# CYBLE_416045_02 register map
File version: 0.1
PSoC 63
Registers are 32-bit, read-write, no defined reset value unless marked. A register's access mark holds for its fields unless they carry their own. Offsets are from the block's base; lines under a group give offsets from that group; [hi:lo] are bit positions; {n}, {i} and the like mark numbered series; 'fields as' and 'values as' point back to an identical list; <NAME> marks a mode.

## Memory map
0x00000000 CapSense_1

## CapSense_1
Base 0x00000000
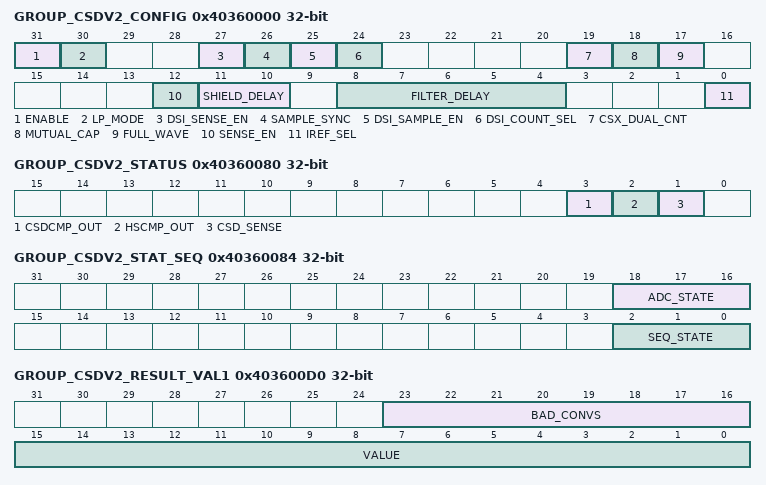
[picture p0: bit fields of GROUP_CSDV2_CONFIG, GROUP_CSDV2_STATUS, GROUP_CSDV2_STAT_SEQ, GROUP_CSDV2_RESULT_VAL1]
0x40360000 GROUP_CSDV2_CONFIG — Configuration and Control
  [31] ENABLE — Master enable of the CSDv2 IP. Must be set to 1 for any CSDv2, ADC or IDAC operation to function.?When 0 all analog components will be off and all switches will be open.
  [30] LP_MODE — Select the power mode for the CSD components (REFGEN, AMBUF, CSDCMP, HSCMP):?0: High Power mode?1: Low Power mode
  [27] DSI_SENSE_EN — Enables the use of the dsi_sense_in input instead of the internally generated modulation signal to drive csd_sense and csd_shield signals.
  [26] SAMPLE_SYNC — Enables double synchronizing of sample input from DSI (only relevant when DSI_SAMPLE_EN=1).
  [25] DSI_SAMPLE_EN — Enables the use of the dsi_sample_in input instead of the comparator output to strobe COUNTER.
  [24] DSI_COUNT_SEL — Select what to output on the dsi_count bus.
    0=CSD_RESULT (depending on the dsi_count_val_sel input either output RESULT_VAL1.VALUE (0) or RESULT_VAL2.VALUE (1) on the dsi_count bus. Note that dsi_count_val_sel is not synchronized, i.e. it controls the mux combinatorially.); 1=ADC_RESULT (output ADC_RES.VIN_CNT on the dsi_count bus)
  [19] CSX_DUAL_CNT — Enable the use of two counters for MUTUAL cap sensing mode (CSX), do not use when MUTUAL_CAP=0
    0=ONE (Use one counter for both phases (source and sink).); 1=TWO (Use two counters, separate count for when csd_sense is high and when csd_sense is low.)
  [18] MUTUAL_CAP — Enables mutual cap sensing mode
    0=SELFCAP (Self-cap mode (configure sense line as CSD_SENSE)); 1=MUTUALCAP (Mutual-cap mode (configure Tx line as CSD_SENSE, inverted Tx line as CSD_SHIELD and Rx Line as AMUXA). In this mode the polarity bit of the IDAC is controlled by csd_sense.)
  [17] FULL_WAVE — Enables full wave cap sensing mode
    0=HALFWAVE (Half Wave mode (normal).?In this mode the comparator always trips in the same direction (positive or negative edge) and the same Vref, i.e. no polarity change.); 1=FULLWAVE (Full Wave mode.?In this mode the comparator trips in opposite direction and with different Vref in each phase, i.e. the polarity flips.)
  [12] SENSE_EN — Enables the sense modulator output. ?0: all switches, static or dynamic, are open and IDAC in CSD mode is off?1: switches and IDAC can be closed/on as per MMIO setting and CSD sequencer.
  [11:10] SHIELD_DELAY — Selects the delay by which csd_shield is delayed relative to csd_sense.
    0=OFF (Delay line is off, csd_shield=csd_sense); 1=D5NS (Introduces a 5ns delay (typ)); 2=D10NS (Introduces a 10ns delay (typ)); 3=D20NS (Introduces a 20ns delay (typ))
  [8:4] FILTER_DELAY — This value determines the number of cycles that the digital filter makes the CSDCMP output ignored while the counter counts and IDAC is on. ?When set to 0 the digital filter is off. When set to any other value the ignoring will last for FILTER_DELAY clk_csd cycles after the start of each measurement and from the first comparator trip to the end of each measurement.
  [0] IREF_SEL — Select Iref supply.
    0=IREF_SRSS (select SRSS Iref (default)); 1=IREF_PASS (select PASS.AREF Iref, only available if PASS IP is on the chip.)
0x40360004 GROUP_CSDV2_SPARE — Spare MMIO
  [3:0] SPARE
0x40360080 GROUP_CSDV2_STATUS — Status Register
  [3] CSDCMP_OUT ro — Output of main sensing comparator (synchronized)
  [2] HSCMP_OUT ro — Output of reference buffer comparator used to charge up Cmod and/or Csh_tank (synchronized)
    0=C_LT_VREF (Vin < Vref); 1=C_GT_VREF (Vin > Vref)
  [1] CSD_SENSE ro — Signal used to drive the Cs switches.
0x40360084 GROUP_CSDV2_STAT_SEQ — Current Sequencer status
  [18:16] ADC_STATE ro — ADC sequencer state (only relevant after SEQ_STATE has reached SAMPLE_NORM and ADC sequencer has started)
  [2:0] SEQ_STATE ro — CSD sequencer state
0x40360088 GROUP_CSDV2_STAT_CNTS — Current status counts
  [15:0] NUM_CONV ro — Current number of conversions remaining when in Sample_* states (note that in AutoZero* states the same down counter is reused to count the cycles)
0x403600D0 GROUP_CSDV2_RESULT_VAL1 — Result CSD/CSX accumulation counter value 1
  [23:16] BAD_CONVS ro — Number of 'bad' conversion for which the CSD comparator did not trigger within the normal time window, either because Vref was not crossed at all, or if the Vref was already crossed before the window started. This counter is reset when the sequencer is started and will saturate at 255 when more than 255 conversions are bad.
  [15:0] VALUE ro — Accumulated counter value for this result. In case of Mutual cap with two counters (CSX = config.mutual_cap & config.csx_dual_cnt) this counter counts when csd_sense is high.
0x403600D4 GROUP_CSDV2_RESULT_VAL2 — Result CSX accumulation counter value 2
  [15:0] VALUE ro — Only used in case of Mutual cap with two counters (CSX = config.mutual_cap & config.csx_dual_cnt), this counter counts when csd_sense is low.
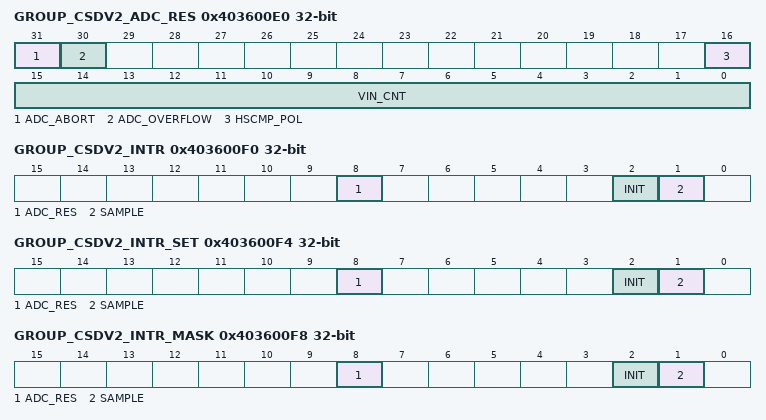
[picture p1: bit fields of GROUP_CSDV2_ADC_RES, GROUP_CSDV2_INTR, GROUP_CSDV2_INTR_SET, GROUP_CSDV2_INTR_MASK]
0x403600E0 GROUP_CSDV2_ADC_RES — ADC measurement
  [31] ADC_ABORT ro — This flag is set when the ADC sequencer was aborted before tripping HSCMP.
  [30] ADC_OVERFLOW ro — This flag is set when the ADC counter overflows. This is an indication to the firmware that the IDACB current level is too low.
  [16] HSCMP_POL ro — Polarity used for IDACB for this last ADC result, 0= source, 1= sink
  [15:0] VIN_CNT ro — Count to source/sink Cref1 + Cref2 from Vin to Vrefhi. This is also the current counter value for the HSCMP counter
0x403600F0 GROUP_CSDV2_INTR — CSD Interrupt Request Register
  [8] ADC_RES — ADC Result ready
  [2] INIT — Coarse initialization complete or Sample initialization complete (the latter is typically ignored)
  [1] SAMPLE — A normal sample is complete
0x403600F4 GROUP_CSDV2_INTR_SET — CSD Interrupt set register
  [8] ADC_RES — Write with '1' to set corresponding bit in interrupt request register.
  [2] INIT — Write with '1' to set corresponding bit in interrupt request register.
  [1] SAMPLE — Write with '1' to set corresponding bit in interrupt request register.
0x403600F8 GROUP_CSDV2_INTR_MASK — CSD Interrupt mask register
  [8] ADC_RES — Mask bit for corresponding bit in interrupt request register.
  [2] INIT — Mask bit for corresponding bit in interrupt request register.
  [1] SAMPLE — Mask bit for corresponding bit in interrupt request register.
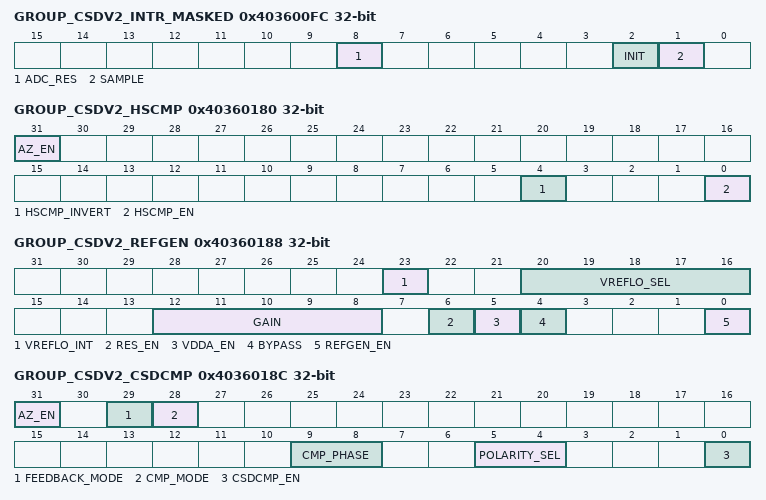
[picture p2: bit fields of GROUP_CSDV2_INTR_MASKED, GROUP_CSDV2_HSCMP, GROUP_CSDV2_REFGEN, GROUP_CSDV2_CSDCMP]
0x403600FC GROUP_CSDV2_INTR_MASKED — CSD Interrupt masked register
  [8] ADC_RES ro — Logical and of corresponding request and mask bits.
  [2] INIT ro — Logical and of corresponding request and mask bits.
  [1] SAMPLE ro — Logical and of corresponding request and mask bits.
0x40360180 GROUP_CSDV2_HSCMP — High Speed Comparator configuration
  [31] AZ_EN — Auto-Zero enable, allow the Sequencer to Auto-Zero this component
  [4] HSCMP_INVERT — Invert the HSCMP output before it is used to control switches and the CSD sequencer. This bit does not affect the ADC sequencer or the STATUS.HSCMP_OUT
  [0] HSCMP_EN — High Speed Comparator enable
    0=OFF (Disable comparator, output is zero); 1=ON (On, regular operation. Note that CONFIG.LP_MODE determines the power mode level)
0x40360184 GROUP_CSDV2_AMBUF — Reference Generator configuration
  [1:0] PWR_MODE — Amux buffer power level
    0=OFF (Disable buffer); 1=NORM (On, normal or low power level depending on CONFIG.LP_MODE.); 2=HI (On, high or low power level depending on CONFIG.LP_MODE.)
0x40360188 GROUP_CSDV2_REFGEN — Reference Generator configuration
  [23] VREFLO_INT — Ouput the resistor string tap either to Vreflo (0) or Vreflo_int (1).
  [20:16] VREFLO_SEL — Select resistor string tap for Vreflo/Vreflo_int, 0= minimum vout, 31= maximum vout = vrefhi (only works if the resistor string is enabled; RES_EN=1)
  [12:8] GAIN — Select resistor string tap for feedback, 0= minimum vout, 31= maximum vout = vrefhi -> gain=1 (only works if the resistor string is enabled; RES_EN=1)
  [6] RES_EN — Resistor string enable; 0= open switch on top of the resistor string (Vreflo=Vssa)
  [5] VDDA_EN — Close Vdda switch to top of resistor string (or Vrefhi?)
  [4] BYPASS — Bypass selected input reference unbuffered to Vrefhi
  [0] REFGEN_EN — Reference Generator Enable
    0=OFF (Disable Reference Generator); 1=ON (On, regular operation. Note that CONFIG.LP_MODE determines the power mode level)
0x4036018C GROUP_CSDV2_CSDCMP — CSD Comparator configuration
  [31] AZ_EN — Auto-Zero enable, allow the Sequencer to Auto-Zero this component
  [29] FEEDBACK_MODE — This bit controls whether the output directly from the comparator (csdcmp_out) or the flopped version (csdcmp_out_ff) is used. For CSD operation, the selected signal controls the IDAC(s), in GP mode the signal goes out on dsi_sample_out.
    0=FLOP (Use feedback from sampling flip-flop (used in most modes).); 1=COMP (Use feedback from comparator directly (used in single Cmod mutual cap sensing only))
  [28] CMP_MODE — Select which signal to output on dsi_sample_out.
    0=CSD (CSD mode: output the filtered sample signal on dsi_sample_out); 1=GP (General Purpose mode: output the unfiltered sample unfiltered comparator output, either asynchronous or flopped.)
  [9:8] CMP_PHASE — Select in what phase(s) the comparator is active, typically set to match the BAL_MODE of the used IDAC. Note, this also determines when a bad conversion is detected, namely at the beginning and end of the comparator active phase (also taking into account FILTER_DELAY and non-overlap).
    0=FULL (Comparator is active from start of Phi2 and kept active into Phi1. Intended usage: legacy CSD for balancing over a full csd_sense period (non-overlap should be turned off)); 1=PHI1 (Comparator is active during Phi1 only. Currently no known use-case.); 2=PHI2 (Comparator is active during Phi2 only. Intended usage: CSD Low EMI.); 3=PHI1_2 (Comparator is activated at the start of both Phi1 and Phi2 (non-overlap should be enabled). Intended usage: CSX, or Full-Wave.)
  [5:4] POLARITY_SEL — Select which IDAC polarity to use to detect CSDCMP triggering
    0=IDACA_POL (Use idaca_pol (firmware setting with CSX and optionally DSI mixed in) to determine the direction, this is the most common use-case, used for normal CSD and normal CSX); 1=IDACB_POL (Use idacb_pol (firmware setting with optional DSI mixed in) to determine the direction, this is only used for normal CSD if IDACB is used i.s.o. IDACA (not common)); 2=DUAL_POL (Use the expression (csd_sense ? idaca_pol : idacb_pol) to determine the direction, this is only useful for the CSX with DUAL_IDAC use-case)
  [0] CSDCMP_EN — CSD Comparator Enable
    values as GROUP_CSDV2_HSCMP.HSCMP_EN
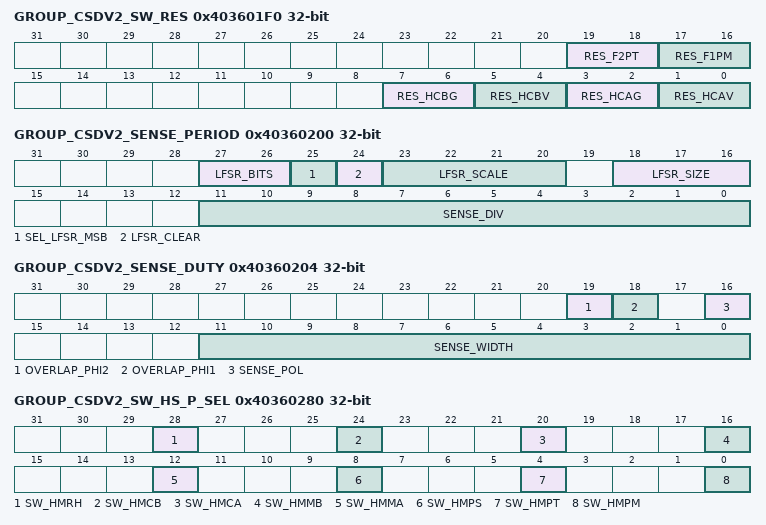
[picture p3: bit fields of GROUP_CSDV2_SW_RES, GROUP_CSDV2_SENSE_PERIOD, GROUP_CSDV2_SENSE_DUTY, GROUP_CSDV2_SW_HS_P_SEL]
0x403601F0 GROUP_CSDV2_SW_RES — Switch Resistance configuration
  [19:18] RES_F2PT — Select resistance for the corresponding switch
  [17:16] RES_F1PM — Select resistance for the corresponding switch
    0=LOW; 1=MED (Medium); 2=HIGH
  [7:6] RES_HCBG — Select resistance or low EMI for the corresponding switch
  [5:4] RES_HCBV — Select resistance or low EMI for the corresponding switch
  [3:2] RES_HCAG — Select resistance or low EMI for the corresponding switch
  [1:0] RES_HCAV — Select resistance or low EMI (slow ramp) for the HCAV switch
    0=LOW; 1=MED (Medium); 2=HIGH; 3=LOWEMI (Low EMI (slow ramp: 3 switches closed by fixed delay line))
0x40360200 GROUP_CSDV2_SENSE_PERIOD — Sense clock period
  [27:26] LFSR_BITS — Selects the number of LSB bits to use from the LSFR to provide the clock dithering variation on the base period.?Caveat make sure that SENSE_DIV > the maximum absolute range (e.g. for 4B SENSE_DIV > 8), otherwise results are undefined.
    0=Cy2B (use 2 bits: range = [-2,1]); 1=Cy3B (use 3 bits: range = [-4,3]); 2=Cy4B (use 4 bits: range = [-8,7]); 3=Cy5B (use 5 bits: range = [-16,15] (default))
  [25] SEL_LFSR_MSB — Use the MSB of configured LSFR size as csd_sense signal. Intended to be used only with bit 8 or 12-bit LFSR size for CSDv1 backward compatibility (PRS). When this bit is set then clock divider dithering is disabled and SENSE_WIDTH is disabled.
  [24] LFSR_CLEAR — When set, forces the LFSR to it's initial state (all ones). This bit is automatically cleared by hardware after the LFSR is cleared, which is at the next clk_csd positive edge. This bit should be set whenever this register is written and the LFSR is used.?Note that the LFSR will also get reset to all ones during the AutoZero_1/2 states.
  [23:20] LFSR_SCALE — Shift the LFSR output left by LSFR_SCALE bits before adding to SENSE_DIV. This dithering is disabled when SEL_LSFR_MSB is set.?The clock divider to be used = (SENSE_DIV+1) + (SEL_LSFR_MSB ? 0 : (LFSR_OUT<<LFSR_SCALE)).?Note that the clock divider including the dithering term must fit in 12 bits, otherwise the result is undefined.
  [18:16] LFSR_SIZE — Selects the length of the LFSR which determines the LFSR repeat period. LFSR_BITS LSB of the LFSR are used for the clock dithering variation on the base period (was PRS in CSDv1). Whenever the LFSR is used (non zero value in this field) the LFSR_CLEAR bit should also be set.
    0=OFF (Don't use clock dithering (=spreadspectrum) (LFSR output value is zero)); 1=Cy6B (6-bit LFSR (G(x)=X^6 +X^4+X^3+ X+1, period= 63)); 2=Cy7B (7-bit LFSR (G(x)=X^7 +X^4+X^3+X^2+1, period= 127)); 3=Cy9B (9-bit LFSR (G(x)=X^9 +X^4+X^3+ X+1, period= 511)); 4=Cy10B (10-bit LFSR (G(x)=X^10+X^4+X^3+ X+1, period= 1023)); 5=Cy8B (8-bit LFSR (G(x)=X^8+X^4+X^3+X^2+1, period= 255)); 6=Cy12B (12-bit LFSR (G(x)=X^12+X^7+X^4+X^3+1, period= 4095))
  [11:0] SENSE_DIV — The length-1 of the Sense modulation 'clock' period in clk_csd cycles. For regular CSD one sense clock cycle = one conversion (=phi1+phi2) .?Note this is the base divider, clock dithering may change the actual period length.?Note that SENSE_DIV must be at least 1 and additionally also allow for one clk_hf of non overlap (if OVERLAP_HI1/2 is set) on both phases, i.e. if clk_csd=clk_hf then SENSE_DIV must be >=3.?In addition the FILTER_DELAY needs to be added to the minimum allowed SENSE_DIV value.
0x40360204 GROUP_CSDV2_SENSE_DUTY — Sense clock duty cycle
  [19] OVERLAP_PHI2 — Same as OVERLAP_PHI1 but for Phi2 (csd_sense=1).
  [18] OVERLAP_PHI1 — NonOverlap or not for Phi1 (csd_sense=0).?0 = Non-overlap for Phi1, the Phi1 signal is csd_sense inverted except that the signal goes low 1 clk_sample before csd_sense goes high. Intended usage: new low EMI CSD/CSX with static GPIO.?1 = 'Overlap' (= not non-overlap) for Phi1, the Phi1 signal is csd_sense inverted. Intended usage: legacy CSD with GPIO switching, the GPIO internal circuit ensures that the switches are non-overlapping.
  [16] SENSE_POL — Polarity of the sense clock?0 = start with low phase (typical for regular negative transfer CSD)?1 = start with high phase
  [11:0] SENSE_WIDTH — Defines the length of the first phase of the sense clock in clk_csd cycles. ?A value of 0 disables this feature and the duty cycle of csd_sense will be 50%, which is equal to SENSE_WIDTH = (SENSE_DIV+1)/2, or when clock dithering is used that becomes [(SENSE_DIV+1) + (LFSR_OUT << LSFR_SCALE)]/2. At all times it must be assured that the phases are at least 2 clk_csd cycles (1 for non overlap, if used), if this rule is violated the result is undefined.?Note that this feature is not available when SEL_LFSR_MSB (PRS) is selected.
0x40360280 GROUP_CSDV2_SW_HS_P_SEL — HSCMP Pos input switch Waveform selection
  [28] SW_HMRH — Set corresponding switch
  [24] SW_HMCB — Set corresponding switch
  [20] SW_HMCA — Set corresponding switch
  [16] SW_HMMB — Set corresponding switch
  [12] SW_HMMA — Set corresponding switch
  [8] SW_HMPS — Set corresponding switch
  [4] SW_HMPT — Set corresponding switch
  [0] SW_HMPM — Set HMPM switch?0: static open?1: static closed
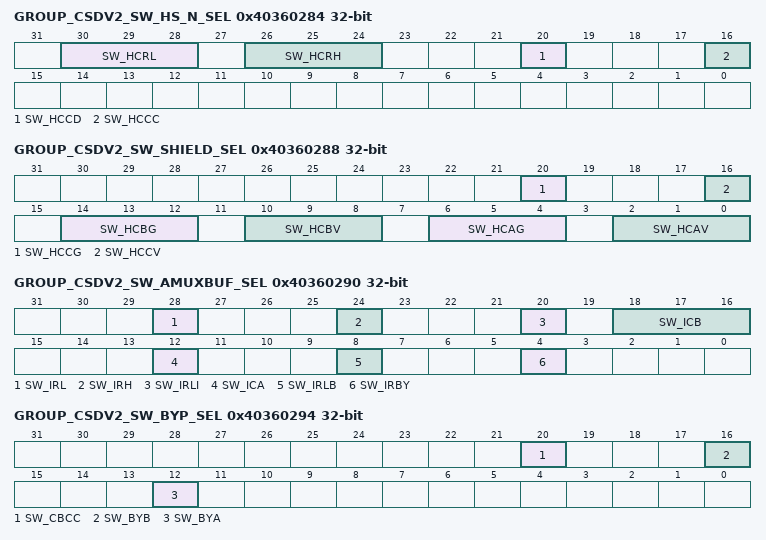
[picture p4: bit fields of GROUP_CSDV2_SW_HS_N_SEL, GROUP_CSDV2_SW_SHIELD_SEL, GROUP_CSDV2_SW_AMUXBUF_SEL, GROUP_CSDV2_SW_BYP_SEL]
0x40360284 GROUP_CSDV2_SW_HS_N_SEL — HSCMP Neg input switch Waveform selection
  [30:28] SW_HCRL — Select waveform for corresponding switch
  [26:24] SW_HCRH — Select waveform for corresponding switch
  [20] SW_HCCD — Set corresponding switch
  [16] SW_HCCC — Set corresponding switch
0x40360288 GROUP_CSDV2_SW_SHIELD_SEL — Shielding switches Waveform selection
  [20] SW_HCCG — Set corresponding switch?If the ADC is enabled then this switch is directly controlled by the ADC sequencer.
  [16] SW_HCCV — Set corresponding switch
  [14:12] SW_HCBG — Select waveform for corresponding switch, using csd_shield as base
  [10:8] SW_HCBV — Select waveform for HCBV switch. The waveform for this switch follows the csd_shield signal, i.e. phi1 and phi2 are delayed with SHIELD_DELAY w.r.t. the csd_sense phases. Only this switch and HCBG use csd_shield as base all other switches use csd_sense as base.?0: static open?1: static closed?2: phi1_delay?3: phi2_delay?4: phi1_delay & HSCMP?5: phi2_delay & HSCMP?6: HSCMP (ignores phi1/2)?7: Reserved
  [6:4] SW_HCAG — Select waveform for corresponding switch
  [2:0] SW_HCAV — Select waveform for HCAV switch using csd_sense as base?0: static open?1: static closed?2: phi1?3: phi2?4: phi1 & HSCMP?5: phi2 & HSCMP?6: HSCMP (ignores phi1/2)?7: Reserved
0x40360290 GROUP_CSDV2_SW_AMUXBUF_SEL — Amuxbuffer switches Waveform selection
  [28] SW_IRL — Set corresponding switch
  [24] SW_IRH — Set corresponding switch
  [20] SW_IRLI — Set corresponding switch
  [18:16] SW_ICB — Select waveform for corresponding switch
  [12] SW_ICA — Set corresponding switch
  [8] SW_IRLB — Set corresponding switch
  [4] SW_IRBY — Set corresponding switch
0x40360294 GROUP_CSDV2_SW_BYP_SEL — AMUXBUS bypass switches Waveform selection
  [20] SW_CBCC — Set corresponding switch?If the ADC is enabled then this switch is directly controlled by the ADC sequencer.
  [16] SW_BYB — Set corresponding switch
  [12] SW_BYA — Set corresponding switch
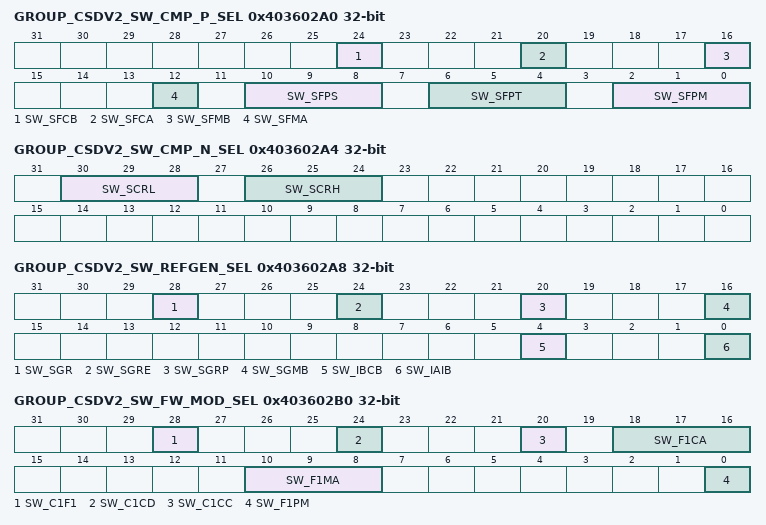
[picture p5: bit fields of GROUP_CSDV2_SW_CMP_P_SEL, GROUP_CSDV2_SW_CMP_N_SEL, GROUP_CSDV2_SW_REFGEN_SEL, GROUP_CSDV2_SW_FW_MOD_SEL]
0x403602A0 GROUP_CSDV2_SW_CMP_P_SEL — CSDCMP Pos Switch Waveform selection
  [24] SW_SFCB — Set corresponding switch
  [20] SW_SFCA — Set corresponding switch
  [16] SW_SFMB — Set corresponding switch
  [12] SW_SFMA — Set corresponding switch
  [10:8] SW_SFPS — Select waveform for corresponding switch
  [6:4] SW_SFPT — Select waveform for corresponding switch
  [2:0] SW_SFPM — Select waveform for corresponding switch
0x403602A4 GROUP_CSDV2_SW_CMP_N_SEL — CSDCMP Neg Switch Waveform selection
  [30:28] SW_SCRL — Select waveform for corresponding switch
  [26:24] SW_SCRH — Select waveform for corresponding switch
0x403602A8 GROUP_CSDV2_SW_REFGEN_SEL — Reference Generator Switch Waveform selection
  [28] SW_SGR — Set corresponding switch
  [24] SW_SGRE — Set corresponding switch
  [20] SW_SGRP — Set corresponding switch
  [16] SW_SGMB — Set corresponding switch
  [4] SW_IBCB — Set corresponding switch
  [0] SW_IAIB — Set corresponding switch
0x403602B0 GROUP_CSDV2_SW_FW_MOD_SEL — Full Wave Cmod Switch Waveform selection
  [28] SW_C1F1 — Set corresponding switch
  [24] SW_C1CD — Set corresponding switch
  [20] SW_C1CC — Set corresponding switch
  [18:16] SW_F1CA — Select waveform for corresponding switch
  [10:8] SW_F1MA — Select waveform for corresponding switch
  [0] SW_F1PM — Set corresponding switch
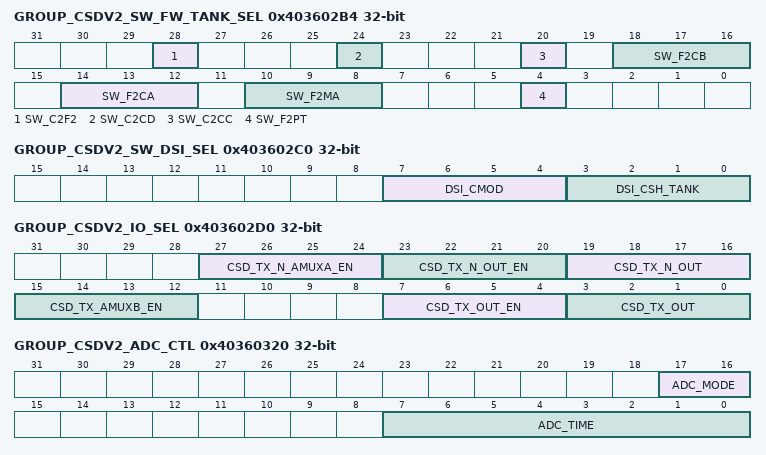
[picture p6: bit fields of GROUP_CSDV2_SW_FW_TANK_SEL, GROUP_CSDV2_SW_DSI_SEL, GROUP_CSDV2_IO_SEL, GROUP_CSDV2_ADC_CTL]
0x403602B4 GROUP_CSDV2_SW_FW_TANK_SEL — Full Wave Csh_tank Switch Waveform selection
  [28] SW_C2F2 — Set corresponding switch
  [24] SW_C2CD — Set corresponding switch
  [20] SW_C2CC — Set corresponding switch
  [18:16] SW_F2CB — Select waveform for corresponding switch
  [14:12] SW_F2CA — Select waveform for corresponding switch
  [10:8] SW_F2MA — Select waveform for corresponding switch
  [4] SW_F2PT — Set corresponding switch
0x403602C0 GROUP_CSDV2_SW_DSI_SEL — DSI output switch control Waveform selection
  [7:4] DSI_CMOD — Select waveform for dsi_cmod output signal
  [3:0] DSI_CSH_TANK — Select waveform for dsi_csh_tank output signal?0: static open?1: static closed?2: phi1?3: phi2?4: phi1 & HSCMP?5: phi2 & HSCMP?6: HSCMP // ignores phi1/2?7: !sense // = phi1 but ignores OVERLAP_PHI1??8: phi1_delay // phi1 delayed with shield delay?9: phi2_delay // phi2 delayed with shield delay??10: !phi1?11: !phi2?12: !(phi1 & HSCMP)?13: !(phi2 & HSCMP)?14: !HSCMP // ignores phi1/2?15: sense // = phi2 but ignores OVERLAP_PHI2
0x403602D0 GROUP_CSDV2_IO_SEL — IO output control Waveform selection
  [27:24] CSD_TX_N_AMUXA_EN — Select waveform for csd_tx_n_amuxa_en output signal
  [23:20] CSD_TX_N_OUT_EN — Select waveform for csd_tx_n_out_en output signal
  [19:16] CSD_TX_N_OUT — Select waveform for csd_tx_n_out output signal
  [15:12] CSD_TX_AMUXB_EN — Select waveform for csd_tx_amuxb_en output signal
  [7:4] CSD_TX_OUT_EN — Select waveform for csd_tx_out_en output signal
  [3:0] CSD_TX_OUT — Select waveform for csd_tx_out output signal
0x40360300 GROUP_CSDV2_SEQ_TIME — Sequencer Timing
  [7:0] AZ_TIME — Define Auto-Zero time in csd_sense cycles -1.
0x40360310 GROUP_CSDV2_SEQ_INIT_CNT — Sequencer Initial conversion and sample counts
  [15:0] CONV_CNT — Number of conversion per Initialization sample, if set to 0 the Sample_init state will be skipped.
0x40360314 GROUP_CSDV2_SEQ_NORM_CNT — Sequencer Normal conversion and sample counts
  [15:0] CONV_CNT — Number of conversion per sample, if set to 0 the Sample_norm state will be skipped.?Sample window size = SEQ_NORM_CNT.CONV_CNT * (SENSE_PERIOD.SENSE_DIV+1).?Note for CSDv1 Sample window size = PERIOD
0x40360320 GROUP_CSDV2_ADC_CTL — ADC Control
  [17:16] ADC_MODE — Enable ADC measurement. When enabled the ADC sequencer will be started when the main sequencer goes to the SAMPLE_NORM state
    0=OFF (No ADC measurement); 1=VREF_CNT (Count time A to bring Cref1 + Cref2 up from Vssa to Vrefhi with IDACB); 2=VREF_BY2_CNT (Count time B to bring Cref1 + Cref2 back up to Vrefhi with IDACB (after bringing them down for time A/2 cycles with IDACB sinking)); 3=VIN_CNT (Determine HSCMP polarity and count time C to source/sink Cref1 + Cref2 from Vin to Vrefhi.)
  [7:0] ADC_TIME — ADC timing -1 in csd_sense clock cycles (actual time is ADC_TIME+1 cycles), either used to discharge Cref1&2, or as the aperture to capture the input voltage on Cref1&2
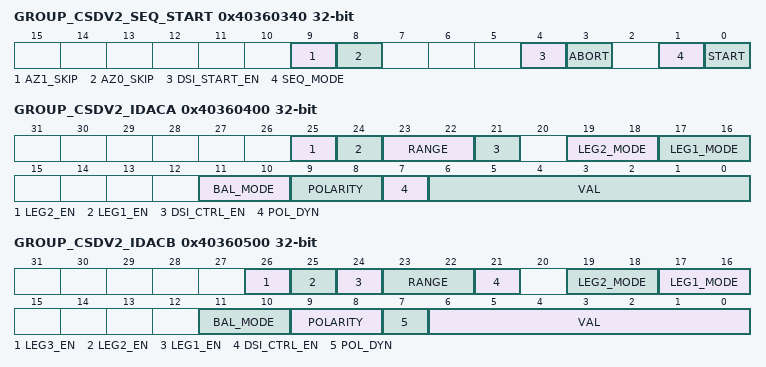
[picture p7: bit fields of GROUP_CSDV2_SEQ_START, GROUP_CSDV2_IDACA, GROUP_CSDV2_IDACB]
0x40360340 GROUP_CSDV2_SEQ_START — Sequencer start
  [9] AZ1_SKIP — When set the AutoZero_1 state will be skipped
  [8] AZ0_SKIP — When set the AutoZero_0 state will be skipped
  [4] DSI_START_EN — When this bit is set a positive edge on dsi_start will start the CSD sequencer and if enabled also the ADC sequencer.
  [3] ABORT — When a 1 is written the CSD and ADC sequencers will be aborted (if they are running) and the START bit will be cleared. This bit always read as 0.
  [1] SEQ_MODE — 0 = regular CSD scan + optional ADC ?1 = coarse initialization, the Sequencer will go to the INIT_COARSE state.
  [0] START — Start the CSD sequencer. The sequencer will clear this bit when it is done. Depending on the mode the sequencer is done when a sample has been accumulated, when the high speed comparator trips or if the sequencer is aborted. When the ADC is enabled the ADC sequencer will start when the CSD sequencer reaches the Sample_norm state (only with the regular CSD scan mode).
0x40360400 GROUP_CSDV2_IDACA — IDACA Configuration
  [25] LEG2_EN — output enable for leg 2 to CSDBUSA
  [24] LEG1_EN — output enable for leg 1 to CSDBUSA
  [23:22] RANGE — IDAC multiplier
    0=IDAC_LO (1 LSB = 37.5 nA); 1=IDAC_MED (1 LSB = 300 nA); 2=IDAC_HI (1 LSB = 2400 nA)
  [21] DSI_CTRL_EN — Mix DSI inputs with MMIO controls or not (before getting mixed with CSD controls if enabled).?0: no DSI control ? IDACA_POLARITY = IDACA.POLARITY ? IDACA_LEG1_EN = IDACA.LEG1_EN ? IDACA_LEG2_EN = IDACA.LEG2_EN ?1: Mix MMIO with DSI control? IDACA_POLARITY = IDACA.POLARITY EXOR dsi_idaca_pol? IDACA_LEG1_EN = IDACA.LEG1_EN AND dsi_idaca_leg1_en ? IDACA_LEG2_EN = IDACA.LEG2_EN AND dsi_idaca_leg2_en
  [19:18] LEG2_MODE — Controls the usage mode of LEG2
    0=GP_STATIC (General Purpose static mode: LEG2 is controlled by MMIO and optionally mixed with DSI (see DSI_CTRL_EN). No shunting is used, this saves power when off but also any on/off switching will take longer.); 1=GP (General Purpose dynamic mode: LEG2 is controlled by MMIO and optionally mixed with DSI (see DSI_CTRL_EN). Shunting is used, so on/off switching is faster, but power is wasted when the leg is disabled.); 2=CSD_STATIC (CSD static mode: LEG2 can only be on when the CSD Sequencer is in the Sample_init or Sample_norm state. In those states LEG2 is controlled by LEG2_EN, csd_sense and the CSD configuration. Polarity is controlled by the CSD configuration and operation. In addition leg2 enable and polarity can optionally be mixed with DSI (see DSI_CTRL_EN). No shunting is used, this saves power when off but also any on/off switching will take longer.); 3=CSD (CSD dynamic mode: LEG2 can only be on when the CSD Sequencer is in the Sample_init or Sample_norm state. In those states LEG2 is controlled by LEG2_EN, the CSD configuration, csd_sense and the flopped CSDCMP output (CSDCMP_OUT_FF). In addition leg2 enable can optionally be mixed with DSI (see DSI_CTRL_EN). Shunting is used, so on/off switching is faster, but power is wasted when the leg is disabled.)
  [17:16] LEG1_MODE — Controls the usage mode of LEG1 and the Polarity bit
    0=GP_STATIC (General Purpose static mode: LEG1 and POLARITY are controlled by MMIO and optionally mixed with DSI (see DSI_CTRL_EN). No shunting is used, this saves power when off but also any on/off switching will take longer.); 1=GP (General Purpose dynamic mode: LEG1 and POLARITY are controlled by MMIO and optionally mixed with DSI (see DSI_CTRL_EN). Shunting is used, so on/off switching is faster, but power is wasted when the leg is disabled.); 2=CSD_STATIC (CSD static mode: LEG1 can only be on when the CSD Sequencer is in the Sample_init or Sample_norm state. In those states LEG1 is controlled by LEG1_EN, csd_sense and the CSD configuration. Polarity is controlled by the CSD configuration and operation. In addition leg1 enable and polarity can optionally be mixed with DSI (see DSI_CTRL_EN). No shunting is used, this saves power when off but also any on/off switching will take longer.); 3=CSD (CSD dynamic mode: LEG1 can only be on when the CSD Sequencer is in the Sample_init or Sample_norm state. In thoses states LEG1 is controlled by LEG1_EN, the CSD configuration, csd_sense and the flopped CSDCMP output (CSDCMP_OUT_FF). Polarity is controlled by the CSD configuration and operation. In addition leg1 enable and polarity can optionally be mixed with DSI (see DSI_CTRL_EN). Shunting is used, so on/off switching is faster, but power is wasted when the leg is disabled.)
  [11:10] BAL_MODE — Balancing mode: only applies to legs configured as CSD.
    0=FULL (enabled from start of Phi2 until disabled by CSDCMP. Intended usage: legacy CSD for balancing over a full csd_sense period (non-overlap should be turned off)); 1=PHI1 (enabled from start of Phi1 and disabled by CSDCMP or at end of Phi1. Enables dual IDAC CSX or Full-Wave, one for sourcing and the other for sinking.); 2=PHI2 (enabled from start of Phi2 and disabled by CSDCMP or at end of Phi2. Intended usage: CSD Low EMI or dual IDAC CSX or Full-Wave.); 3=PHI1_2 (enabled from start of both Phi1 and Phi2 and disabled by CSDCMP or at end of Phi1 or Phi2 (if non-overlap enabled). Intended usage: single IDAC CSX, or Full-Wave.)
  [9:8] POLARITY — Selects the polarity of the IDAC (sensing operation). Normally the actual polarity depends on this bit, optionally mixed with DSI (see DSI_CTRL_EN) and if LEG1_MODE==CSD also mixed with the CSD configuration and operation. However in mutual cap mode with one IDAC (config.mutual_cap=1 & config.csx_dual_idac=0) the polarity of the IDAC is controlled by csd_sense.
    0=VSSA_SRC (Normal: switch between Vssa and Cmod. For non-CSD application, IDAC will source current.); 1=VDDA_SNK (Inverted: switch between Vdda and Cmod. For non-CSD application, IDAC will sink current.); 2=SENSE (The polarity of the IDAC will follow the csd_sense signal (POL_DYN bit should be set too). The intended usage is for CSX using a single IDAC.); 3=SENSE_INV (The polarity of the IDAC will follow the inverted csd_sense signal (POL_DYN bit should be set too). The intended usage is for CSX using a single IDAC.)
  [7] POL_DYN — Polarity is dynamic, this bit does not influence the logic in the SoftIP, it only goes to the HardIP.
    0=STATIC (Static polarity. Polarity is expected to be stable, so to save power this avoids the shunting of the unused polarity, at the expense of response time.); 1=DYNAMIC (Dynamic polarity. Polarity is expected to change frequently (e.g. invert after every csd_sense phase), so to improve response time this keeps the shunt of the unused polarity on at the expense of power.)
  [6:0] VAL — Current value setting for this IDAC (7 bits).
0x40360500 GROUP_CSDV2_IDACB — IDACB Configuration
  [26] LEG3_EN — output enable for leg3 to CSDBUSC, only allowed when RANGE = IDAC_LO. When this bit is set both other legs should be off.?Note that leg3 can only be used for ADC mode, not GP mode. Which means that leg3 can only be on when the ADC Sequencer is in the ADC_measure or Calib_measure state. In those states leg3 is controlled by the ADC configuration and the HSCMP output. In addition this leg3 enable bit can optionally be mixed with DSI (see DSI_CTRL_EN).?When LEG3_EN=1 also the IDACB polarity is controlled by the ADC sequencer.
  [25] LEG2_EN — output enable for leg 2 to CSDBUSB or CSDBUSA
  [24] LEG1_EN — output enable for leg 1 to CSDBUSB or CSDBUSA
  [23:22] RANGE — IDAC multiplier
    values as GROUP_CSDV2_IDACA.RANGE
  [21] DSI_CTRL_EN — Mix DSI inputs with MMIO controls or not (before getting mixed with CSD controls if enabled)?0: no DSI control? IDACB_POLARITY = IDACB.POLARITY ? IDACB_LEG1_EN = IDACB.LEG1_EN ? IDACB_LEG2_EN = IDACB.LEG2_EN ? IDACB_LEG3_EN = IDACB.LEG3_EN ?1: Mix MMIO with DSI control? IDACB_POLARITY = IDACB.POLARITY EXOR dsi_idacb_pol? IDACB_LEG1_EN = IDACB.LEG1_EN AND dsi_idacb_leg1_en ? IDACB_LEG2_EN = IDACB.LEG2_EN AND dsi_idacb_leg2_en ? IDACB_LEG3_EN = IDACB.LEG3_EN AND dsi_idacb_leg3_en
  [19:18] LEG2_MODE — Controls the usage mode of LEG2
    0=GP_STATIC (same as corresponding IDACA.LEG2_MODE); 1=GP (same as corresponding IDACA.LEG2_MODE); 2=CSD_STATIC (same as corresponding IDACA.LEG2_MODE); 3=CSD (same as corresponding IDACA.LEG2_MODE)
  [17:16] LEG1_MODE — Controls the usage mode of LEG1 and the Polarity bit
    0=GP_STATIC (same as corresponding IDACA.LEG1_MODE); 1=GP (same as corresponding IDACA.LEG1_MODE); 2=CSD_STATIC (same as corresponding IDACA.LEG1_MODE); 3=CSD (same as corresponding IDACA.LEG1_MODE)
  [11:10] BAL_MODE — same as corresponding IDACA Balancing mode
    0=FULL (same as corresponding IDACA Balancing mode); 1=PHI1 (same as corresponding IDACA Balancing mode); 2=PHI2 (same as corresponding IDACA Balancing mode); 3=PHI1_2 (same as corresponding IDACA Balancing mode)
  [9:8] POLARITY — Selects the polarity of the IDAC (sensing operation). Normally the actual polarity depends on this bit, optionally mixed with DSI (see DSI_CTRL_EN) and if LEG1_EN==1 and LEG1_MODE==CSD also mixed with the CSD configuration and operation. In mutual cap mode however (see config.mutual_cap) the polarity of the IDAC is controlled by csd_sense. If LEG3_EN=1 (the other two legs must be off) then the ADC sequencer controls the IDACB polarity, optionally mixed with DSI.
    values as GROUP_CSDV2_IDACA.POLARITY
  [7] POL_DYN — Polarity is dynamic, this bit does not influence the logic in the SoftIP, it only goes to the HardIP.
    values as GROUP_CSDV2_IDACA.POL_DYN
  [6:0] VAL — Current value setting for this IDAC (7 bits).
